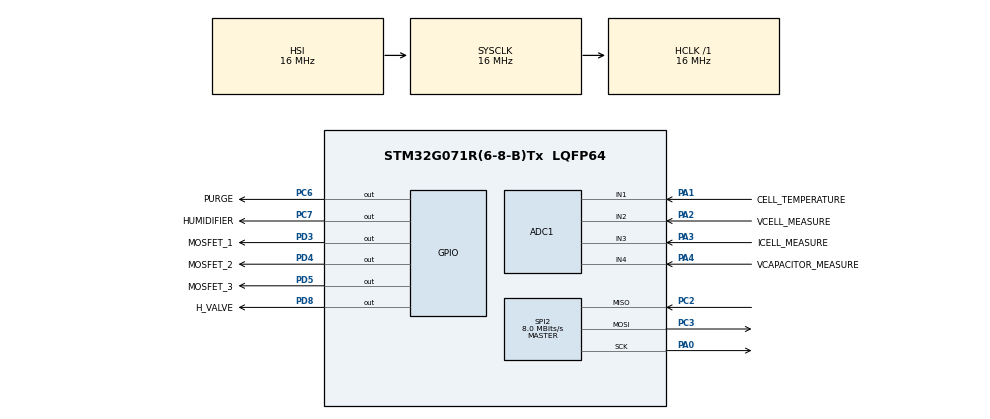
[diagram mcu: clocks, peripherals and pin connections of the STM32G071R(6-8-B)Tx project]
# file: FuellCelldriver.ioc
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ADC1.Channel-0\#ChannelRegularConversion=ADC_CHANNEL_1
ADC1.NbrOfConversionFlag=1
ADC1.Rank-0\#ChannelRegularConversion=1
ADC1.SamplingTime-0\#ChannelRegularConversion=ADC_SAMPLINGTIME_COMMON_1
ADC1.SelectedChannel=ADC_CHANNEL_1|ADC_CHANNEL_2|ADC_CHANNEL_3|ADC_CHANNEL_4
ADC1.master=1
Mcu.Family=STM32G0
Mcu.Name=STM32G071R(6-8-B)Tx
Mcu.Package=LQFP64
PA0.Mode=Full_Duplex_Master
PA0.Signal=SPI2_SCK
PA1.GPIO_Label=CELL_TEMPERATURE
PA1.Mode=IN1
PA1.Signal=ADC1_IN1
PA13.Mode=Serial_Wire
PA13.Signal=SYS_SWDIO
PA14-BOOT0.Mode=Serial_Wire
PA14-BOOT0.Signal=SYS_SWCLK
PA2.GPIO_Label=VCELL_MEASURE
PA2.Mode=IN2
PA2.Signal=ADC1_IN2
PA3.GPIO_Label=ICELL_MEASURE
PA3.Mode=IN3
PA3.Signal=ADC1_IN3
PA4.GPIO_Label=VCAPACITOR_MEASURE
PA4.Mode=IN4
PA4.Signal=ADC1_IN4
PB0.GPIO_Label=BLOWER
PB0.Signal=S_TIM3_CH3
PB1.GPIO_Label=BLOWER_PWM
PB1.Signal=S_TIM3_CH4
PC2.Mode=Full_Duplex_Master
PC2.Signal=SPI2_MISO
PC3.Mode=Full_Duplex_Master
PC3.Signal=SPI2_MOSI
PC6.GPIO_Label=PURGE
PC6.Signal=GPIO_Output
PC7.GPIO_Label=HUMIDIFIER
PC7.Signal=GPIO_Output
PD3.GPIO_Label=MOSFET_1
PD3.Signal=GPIO_Output
PD4.GPIO_Label=MOSFET_2
PD4.Signal=GPIO_Output
PD5.GPIO_Label=MOSFET_3
PD5.Signal=GPIO_Output
PD8.GPIO_Label=H_VALVE
PD8.Signal=GPIO_Output
ProjectManager.HeapSize=0x200
ProjectManager.StackSize=0x400
ProjectManager.TargetToolchain=STM32CubeIDE
RCC.AHBFreq_Value=16000000
RCC.CortexFreq_Value=16000000
RCC.EXTERNAL_CLOCK_VALUE=48000
RCC.HCLKFreq_Value=16000000
RCC.HSE_VALUE=8000000
RCC.HSI_VALUE=16000000
RCC.LSE_VALUE=32768
RCC.SYSCLKFreq_VALUE=16000000
RCC.VCOOutputFreq_Value=128000000
SH.S_TIM3_CH3.0=TIM3_CH3
SH.S_TIM3_CH4.0=TIM3_CH4
SPI2.CalculateBaudRate=8.0 MBits/s
SPI2.Direction=SPI_DIRECTION_2LINES
SPI2.Mode=SPI_MODE_MASTER
SPI2.VirtualType=VM_MASTER
VP_TIM6_VS_ClockSourceINT.Mode=Enable_Timer
board=custom

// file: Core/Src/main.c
/* USER CODE BEGIN Header */
/**
  ******************************************************************************
  * @file           : main.c
  * @brief          : Main program body
  ******************************************************************************
  * @attention
  *
  * Copyright (c) 2025 STMicroelectronics.
  * All rights reserved.
  *
  * This software is licensed under terms that can be found in the LICENSE file
  * in the root directory of this software component.
  * If no LICENSE file comes with this software, it is provided AS-IS.
  *
  ******************************************************************************
  */
/* USER CODE END Header */
#include "main.h"

/* USER CODE BEGIN Includes */
#include "measurments.h"
/* USER CODE END Includes */

ADC_HandleTypeDef hadc1;

SPI_HandleTypeDef hspi2;

TIM_HandleTypeDef htim6;

void SystemClock_Config(void);
static void MX_GPIO_Init(void);
static void MX_ADC1_Init(void);
static void MX_SPI2_Init(void);
static void MX_TIM6_Init(void);

int main(void)
{

  /* MCU Configuration--------------------------------------------------------*/

  /* Reset of all peripherals, Initializes the Flash interface and the Systick. */
  HAL_Init();

  /* Configure the system clock */
  SystemClock_Config();

  /* Initialize all configured peripherals */
  MX_GPIO_Init();
  MX_ADC1_Init();
  MX_SPI2_Init();
  MX_TIM6_Init();

  /* Infinite loop */
  /* USER CODE BEGIN WHILE */
  while (1)
  {
	  float CapacitorVoltage = Read_ADC_Value(4);
	  float CellVoltage = Read_ADC_Value(2);

    /* USER CODE END WHILE */

  }
}

void SystemClock_Config(void)
{
  RCC_OscInitTypeDef RCC_OscInitStruct = {0};
  RCC_ClkInitTypeDef RCC_ClkInitStruct = {0};

  /** Configure the main internal regulator output voltage
  */
  HAL_PWREx_ControlVoltageScaling(PWR_REGULATOR_VOLTAGE_SCALE1);

  /** Initializes the RCC Oscillators according to the specified parameters
  * in the RCC_OscInitTypeDef structure.
  */
  RCC_OscInitStruct.OscillatorType = RCC_OSCILLATORTYPE_HSI;
  RCC_OscInitStruct.HSIState = RCC_HSI_ON;
  RCC_OscInitStruct.HSIDiv = RCC_HSI_DIV1;
  RCC_OscInitStruct.HSICalibrationValue = RCC_HSICALIBRATION_DEFAULT;
  RCC_OscInitStruct.PLL.PLLState = RCC_PLL_NONE;
  if (HAL_RCC_OscConfig(&RCC_OscInitStruct) != HAL_OK)
  {
    Error_Handler();
  }

  /** Initializes the CPU, AHB and APB buses clocks
  */
  RCC_ClkInitStruct.ClockType = RCC_CLOCKTYPE_HCLK|RCC_CLOCKTYPE_SYSCLK
                              |RCC_CLOCKTYPE_PCLK1;
  RCC_ClkInitStruct.SYSCLKSource = RCC_SYSCLKSOURCE_HSI;
  RCC_ClkInitStruct.AHBCLKDivider = RCC_SYSCLK_DIV1;
  RCC_ClkInitStruct.APB1CLKDivider = RCC_HCLK_DIV1;

  if (HAL_RCC_ClockConfig(&RCC_ClkInitStruct, FLASH_LATENCY_0) != HAL_OK)
  {
    Error_Handler();
  }
}

static void MX_ADC1_Init(void)
{

  ADC_ChannelConfTypeDef sConfig = {0};

  /** Configure the global features of the ADC (Clock, Resolution, Data Alignment and number of conversion)
  */
  hadc1.Instance = ADC1;
  hadc1.Init.ClockPrescaler = ADC_CLOCK_SYNC_PCLK_DIV2;
  hadc1.Init.Resolution = ADC_RESOLUTION_12B;
  hadc1.Init.DataAlign = ADC_DATAALIGN_RIGHT;
  hadc1.Init.ScanConvMode = ADC_SCAN_DISABLE;
  hadc1.Init.EOCSelection = ADC_EOC_SINGLE_CONV;
  hadc1.Init.LowPowerAutoWait = DISABLE;
  hadc1.Init.LowPowerAutoPowerOff = DISABLE;
  hadc1.Init.ContinuousConvMode = DISABLE;
  hadc1.Init.NbrOfConversion = 1;
  hadc1.Init.DiscontinuousConvMode = DISABLE;
  hadc1.Init.ExternalTrigConv = ADC_SOFTWARE_START;
  hadc1.Init.ExternalTrigConvEdge = ADC_EXTERNALTRIGCONVEDGE_NONE;
  hadc1.Init.DMAContinuousRequests = DISABLE;
  hadc1.Init.Overrun = ADC_OVR_DATA_PRESERVED;
  hadc1.Init.SamplingTimeCommon1 = ADC_SAMPLETIME_1CYCLE_5;
  hadc1.Init.SamplingTimeCommon2 = ADC_SAMPLETIME_1CYCLE_5;
  hadc1.Init.OversamplingMode = DISABLE;
  hadc1.Init.TriggerFrequencyMode = ADC_TRIGGER_FREQ_HIGH;
  if (HAL_ADC_Init(&hadc1) != HAL_OK)
  {
    Error_Handler();
  }

  /** Configure Regular Channel
  */
  sConfig.Channel = ADC_CHANNEL_1;
  sConfig.Rank = ADC_REGULAR_RANK_1;
  sConfig.SamplingTime = ADC_SAMPLINGTIME_COMMON_1;
  if (HAL_ADC_ConfigChannel(&hadc1, &sConfig) != HAL_OK)
  {
    Error_Handler();
  }

}

static void MX_SPI2_Init(void)
{

  /* SPI2 parameter configuration*/
  hspi2.Instance = SPI2;
  hspi2.Init.Mode = SPI_MODE_MASTER;
  hspi2.Init.Direction = SPI_DIRECTION_2LINES;
  hspi2.Init.DataSize = SPI_DATASIZE_4BIT;
  hspi2.Init.CLKPolarity = SPI_POLARITY_LOW;
  hspi2.Init.CLKPhase = SPI_PHASE_1EDGE;
  hspi2.Init.NSS = SPI_NSS_SOFT;
  hspi2.Init.BaudRatePrescaler = SPI_BAUDRATEPRESCALER_2;
  hspi2.Init.FirstBit = SPI_FIRSTBIT_MSB;
  hspi2.Init.TIMode = SPI_TIMODE_DISABLE;
  hspi2.Init.CRCCalculation = SPI_CRCCALCULATION_DISABLE;
  hspi2.Init.CRCPolynomial = 7;
  hspi2.Init.CRCLength = SPI_CRC_LENGTH_DATASIZE;
  hspi2.Init.NSSPMode = SPI_NSS_PULSE_ENABLE;
  if (HAL_SPI_Init(&hspi2) != HAL_OK)
  {
    Error_Handler();
  }

}

static void MX_TIM6_Init(void)
{

  TIM_MasterConfigTypeDef sMasterConfig = {0};

  htim6.Instance = TIM6;
  htim6.Init.Prescaler = 0;
  htim6.Init.CounterMode = TIM_COUNTERMODE_UP;
  htim6.Init.Period = 65535;
  htim6.Init.AutoReloadPreload = TIM_AUTORELOAD_PRELOAD_DISABLE;
  if (HAL_TIM_Base_Init(&htim6) != HAL_OK)
  {
    Error_Handler();
  }
  sMasterConfig.MasterOutputTrigger = TIM_TRGO_RESET;
  sMasterConfig.MasterSlaveMode = TIM_MASTERSLAVEMODE_DISABLE;
  if (HAL_TIMEx_MasterConfigSynchronization(&htim6, &sMasterConfig) != HAL_OK)
  {
    Error_Handler();
  }

}

static void MX_GPIO_Init(void)
{
  GPIO_InitTypeDef GPIO_InitStruct = {0};

  /* GPIO Ports Clock Enable */
  __HAL_RCC_GPIOC_CLK_ENABLE();
  __HAL_RCC_GPIOA_CLK_ENABLE();
  __HAL_RCC_GPIOB_CLK_ENABLE();
  __HAL_RCC_GPIOD_CLK_ENABLE();

  /*Configure GPIO pin Output Level */
  HAL_GPIO_WritePin(GPIOC, PURGE_Pin|HUMIDIFIER_Pin, GPIO_PIN_RESET);

  /*Configure GPIO pin Output Level */
  HAL_GPIO_WritePin(GPIOD, H_VALVE_Pin|MOSFET_1_Pin|MOSFET_2_Pin|MOSFET_3_Pin, GPIO_PIN_RESET);

  /*Configure GPIO pins : BLOWER_Pin BLOWER_PWM_Pin */
  GPIO_InitStruct.Pin = BLOWER_Pin|BLOWER_PWM_Pin;
  GPIO_InitStruct.Mode = GPIO_MODE_AF_PP;
  GPIO_InitStruct.Pull = GPIO_NOPULL;
  GPIO_InitStruct.Speed = GPIO_SPEED_FREQ_LOW;
  GPIO_InitStruct.Alternate = GPIO_AF1_TIM3;
  HAL_GPIO_Init(GPIOB, &GPIO_InitStruct);

  /*Configure GPIO pins : PURGE_Pin HUMIDIFIER_Pin */
  GPIO_InitStruct.Pin = PURGE_Pin|HUMIDIFIER_Pin;
  GPIO_InitStruct.Mode = GPIO_MODE_OUTPUT_PP;
  GPIO_InitStruct.Pull = GPIO_NOPULL;
  GPIO_InitStruct.Speed = GPIO_SPEED_FREQ_LOW;
  HAL_GPIO_Init(GPIOC, &GPIO_InitStruct);

  /*Configure GPIO pins : H_VALVE_Pin MOSFET_1_Pin MOSFET_2_Pin MOSFET_3_Pin */
  GPIO_InitStruct.Pin = H_VALVE_Pin|MOSFET_1_Pin|MOSFET_2_Pin|MOSFET_3_Pin;
  GPIO_InitStruct.Mode = GPIO_MODE_OUTPUT_PP;
  GPIO_InitStruct.Pull = GPIO_NOPULL;
  GPIO_InitStruct.Speed = GPIO_SPEED_FREQ_LOW;
  HAL_GPIO_Init(GPIOD, &GPIO_InitStruct);

}

void Error_Handler(void)
{
  __disable_irq();
  while (1)
  {
  }
}
